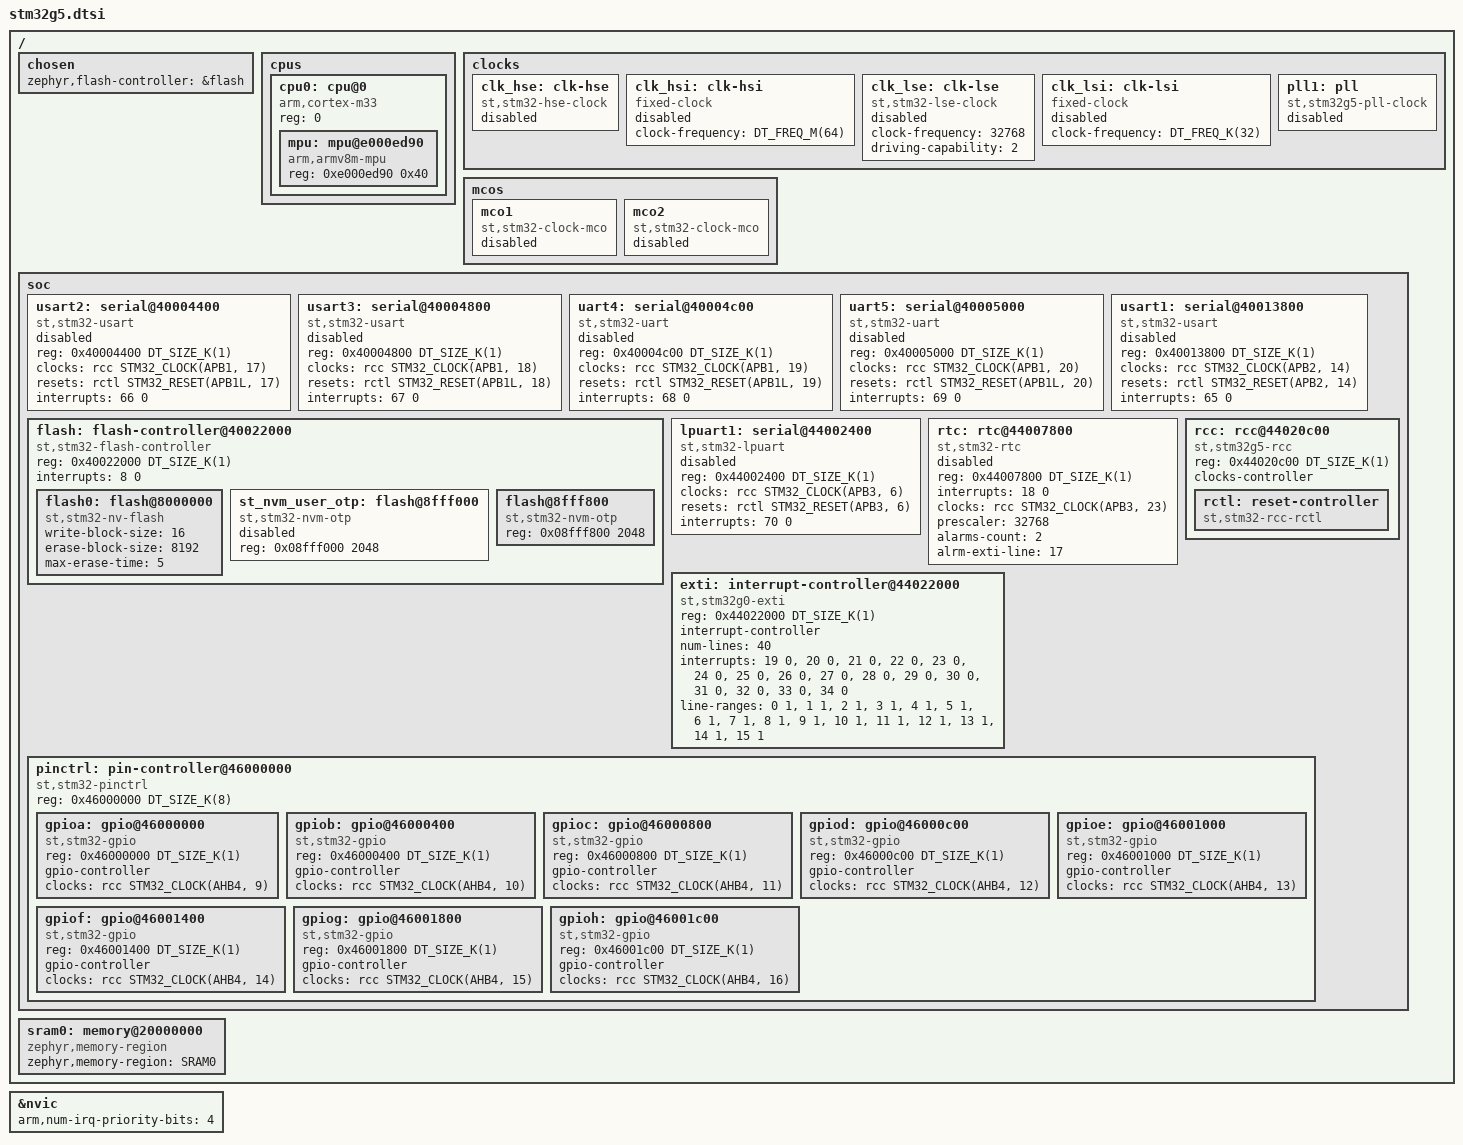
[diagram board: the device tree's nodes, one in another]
/*
 * Copyright (c) 2026 STMicroelectronics
 *
 * SPDX-License-Identifier: Apache-2.0
 */

#include <arm/armv8-m.dtsi>
#include <zephyr/dt-bindings/adc/adc.h>
#include <zephyr/dt-bindings/clock/stm32g5_clock.h>
#include <zephyr/dt-bindings/dma/stm32_dma.h>
#include <zephyr/dt-bindings/gpio/gpio.h>
#include <zephyr/dt-bindings/i2c/i2c.h>
#include <zephyr/dt-bindings/reset/stm32g5_reset.h>
#include <zephyr/dt-bindings/sensor/qdec_stm32.h>
#include <zephyr/dt-bindings/pwm/pwm.h>
#include <freq.h>

/ {
	chosen {
		zephyr,flash-controller = &flash;
	};

	cpus {
		#address-cells = <1>;
		#size-cells = <0>;

		cpu0: cpu@0 {
			compatible = "arm,cortex-m33";
			reg = <0>;
			device_type = "cpu";
			#address-cells = <1>;
			#size-cells = <1>;

			mpu: mpu@e000ed90 {
				compatible = "arm,armv8m-mpu";
				reg = <0xe000ed90 0x40>;
			};
		};
	};

	clocks {
		clk_hse: clk-hse {
			compatible = "st,stm32-hse-clock";
			#clock-cells = <0>;
			status = "disabled";
		};

		clk_hsi: clk-hsi {
			compatible = "fixed-clock";
			#clock-cells = <0>;
			clock-frequency = <DT_FREQ_M(64)>;
			status = "disabled";
		};

		clk_lse: clk-lse {
			compatible = "st,stm32-lse-clock";
			#clock-cells = <0>;
			clock-frequency = <32768>;
			driving-capability = <2>;
			status = "disabled";
		};

		clk_lsi: clk-lsi {
			compatible = "fixed-clock";
			#clock-cells = <0>;
			clock-frequency = <DT_FREQ_K(32)>;
			status = "disabled";
		};

		pll1: pll: pll {
			compatible = "st,stm32g5-pll-clock", "st,stm32u5-pll-clock";
			#clock-cells = <0>;
			status = "disabled";
		};
	};

	mcos {
		mco1: mco1 {
			compatible = "st,stm32-clock-mco";
			clock-names = "clksel";
			status = "disabled";
		};

		mco2: mco2 {
			compatible = "st,stm32-clock-mco";
			clock-names = "clksel";
			status = "disabled";
		};
	};

	soc {
		usart2: serial@40004400 {
			compatible = "st,stm32-usart", "st,stm32-uart";
			reg = <0x40004400 DT_SIZE_K(1)>;
			clocks = <&rcc STM32_CLOCK(APB1, 17)>;
			resets = <&rctl STM32_RESET(APB1L, 17)>;
			interrupts = <66 0>;
			interrupt-names = "global";
			status = "disabled";
		};

		usart3: serial@40004800 {
			compatible = "st,stm32-usart", "st,stm32-uart";
			reg = <0x40004800 DT_SIZE_K(1)>;
			clocks = <&rcc STM32_CLOCK(APB1, 18)>;
			resets = <&rctl STM32_RESET(APB1L, 18)>;
			interrupts = <67 0>;
			interrupt-names = "global";
			status = "disabled";
		};

		uart4: serial@40004c00 {
			compatible = "st,stm32-uart";
			reg = <0x40004c00 DT_SIZE_K(1)>;
			clocks = <&rcc STM32_CLOCK(APB1, 19)>;
			resets = <&rctl STM32_RESET(APB1L, 19)>;
			interrupts = <68 0>;
			interrupt-names = "global";
			status = "disabled";
		};

		uart5: serial@40005000 {
			compatible = "st,stm32-uart";
			reg = <0x40005000 DT_SIZE_K(1)>;
			clocks = <&rcc STM32_CLOCK(APB1, 20)>;
			resets = <&rctl STM32_RESET(APB1L, 20)>;
			interrupts = <69 0>;
			interrupt-names = "global";
			status = "disabled";
		};

		usart1: serial@40013800 {
			compatible = "st,stm32-usart", "st,stm32-uart";
			reg = <0x40013800 DT_SIZE_K(1)>;
			clocks = <&rcc STM32_CLOCK(APB2, 14)>;
			resets = <&rctl STM32_RESET(APB2, 14)>;
			interrupts = <65 0>;
			interrupt-names = "global";
			status = "disabled";
		};

		flash: flash-controller@40022000 {
			compatible = "st,stm32-flash-controller", "st,stm32g5-flash-controller";
			reg = <0x40022000 DT_SIZE_K(1)>;
			ranges;
			interrupts = <8 0>;
			interrupt-names = "global";

			#address-cells = <1>;
			#size-cells = <1>;

			flash0: flash@8000000 {
				compatible = "st,stm32-nv-flash", "soc-nv-flash";
				#address-cells = <1>;
				#size-cells = <1>;
				write-block-size = <16>;
				erase-block-size = <8192>;
				max-erase-time = <5>;
			};

			st_nvm_user_otp: flash@8fff000 {
				compatible = "st,stm32-nvm-otp";
				reg = <0x08fff000 2048>;
				status = "disabled";
			};

			flash@8fff800 {
				compatible = "st,stm32-nvm-otp";
				reg = <0x08fff800 2048>;
			};
		};

		lpuart1: serial@44002400 {
			compatible = "st,stm32-lpuart", "st,stm32-uart";
			reg = <0x44002400 DT_SIZE_K(1)>;
			clocks = <&rcc STM32_CLOCK(APB3, 6)>;
			resets = <&rctl STM32_RESET(APB3, 6)>;
			interrupts = <70 0>;
			interrupt-names = "global";
			status = "disabled";
		};

		rtc: rtc@44007800 {
			compatible = "st,stm32-rtc";
			reg = <0x44007800 DT_SIZE_K(1)>;
			interrupts = <18 0>;
			interrupt-names = "global";
			clocks = <&rcc STM32_CLOCK(APB3, 23)>;
			prescaler = <32768>;
			alarms-count = <2>;
			alrm-exti-line = <17>;
			status = "disabled";
		};

		rcc: rcc@44020c00 {
			compatible = "st,stm32g5-rcc";
			reg = <0x44020c00 DT_SIZE_K(1)>;
			clocks-controller;
			#clock-cells = <2>;

			rctl: reset-controller {
				compatible = "st,stm32-rcc-rctl";
				#reset-cells = <1>;
			};
		};

		exti: interrupt-controller@44022000 {
			compatible = "st,stm32g0-exti", "st,stm32-exti";
			reg = <0x44022000 DT_SIZE_K(1)>;
			interrupt-controller;
			#interrupt-cells = <1>;
			#address-cells = <1>;
			num-lines = <40>;
			interrupts = <19 0>, <20 0>, <21 0>, <22 0>,
				     <23 0>, <24 0>, <25 0>, <26 0>,
				     <27 0>, <28 0>, <29 0>, <30 0>,
				     <31 0>, <32 0>, <33 0>, <34 0>;
			interrupt-names = "line0", "line1", "line2", "line3",
					  "line4", "line5", "line6", "line7",
					  "line8", "line9", "line10", "line11",
					  "line12", "line13", "line14", "line15";
			line-ranges = <0 1>, <1 1>, <2 1>, <3 1>,
				      <4 1>, <5 1>, <6 1>, <7 1>,
				      <8 1>, <9 1>, <10 1>, <11 1>,
				      <12 1>, <13 1>, <14 1>, <15 1>;
		};

		pinctrl: pin-controller@46000000 {
			compatible = "st,stm32-pinctrl";
			reg = <0x46000000 DT_SIZE_K(8)>;
			#address-cells = <1>;
			#size-cells = <1>;

			gpioa: gpio@46000000 {
				compatible = "st,stm32-gpio";
				reg = <0x46000000 DT_SIZE_K(1)>;
				gpio-controller;
				#gpio-cells = <2>;
				clocks = <&rcc STM32_CLOCK(AHB4, 9)>;
			};

			gpiob: gpio@46000400 {
				compatible = "st,stm32-gpio";
				reg = <0x46000400 DT_SIZE_K(1)>;
				gpio-controller;
				#gpio-cells = <2>;
				clocks = <&rcc STM32_CLOCK(AHB4, 10)>;
			};

			gpioc: gpio@46000800 {
				compatible = "st,stm32-gpio";
				reg = <0x46000800 DT_SIZE_K(1)>;
				gpio-controller;
				#gpio-cells = <2>;
				clocks = <&rcc STM32_CLOCK(AHB4, 11)>;
			};

			gpiod: gpio@46000c00 {
				compatible = "st,stm32-gpio";
				reg = <0x46000c00 DT_SIZE_K(1)>;
				gpio-controller;
				#gpio-cells = <2>;
				clocks = <&rcc STM32_CLOCK(AHB4, 12)>;
			};

			gpioe: gpio@46001000 {
				compatible = "st,stm32-gpio";
				reg = <0x46001000 DT_SIZE_K(1)>;
				gpio-controller;
				#gpio-cells = <2>;
				clocks = <&rcc STM32_CLOCK(AHB4, 13)>;
			};

			gpiof: gpio@46001400 {
				compatible = "st,stm32-gpio";
				reg = <0x46001400 DT_SIZE_K(1)>;
				gpio-controller;
				#gpio-cells = <2>;
				clocks = <&rcc STM32_CLOCK(AHB4, 14)>;
			};

			gpiog: gpio@46001800 {
				compatible = "st,stm32-gpio";
				reg = <0x46001800 DT_SIZE_K(1)>;
				gpio-controller;
				#gpio-cells = <2>;
				clocks = <&rcc STM32_CLOCK(AHB4, 15)>;
			};

			gpioh: gpio@46001c00 {
				compatible = "st,stm32-gpio";
				reg = <0x46001c00 DT_SIZE_K(1)>;
				gpio-controller;
				#gpio-cells = <2>;
				clocks = <&rcc STM32_CLOCK(AHB4, 16)>;
			};
		};
	};

	sram0: memory@20000000 {
		compatible = "zephyr,memory-region", "mmio-sram";
		zephyr,memory-region = "SRAM0";
	};
};

&nvic {
	arm,num-irq-priority-bits = <4>;
};
